# GD32C211 register map
File version: 1.0
GD32C211 ARM 32-bit Cortex-M23 Microcontroller based device
CPU: CM23 r0p0, little endian, MPU, FPU, 4 interrupt priority bits
Registers are 32-bit, read-write, reset 0x0 unless marked. A register's access mark holds for its fields unless they carry their own. Offsets are from the block's base; lines under a group give offsets from that group; [hi:lo] are bit positions; {n}, {i} and the like mark numbered series; 'fields as' and 'values as' point back to an identical list; <NAME> marks a mode.

## Memory map
0x40000400 TIMER2 size 0x400 — General-level0-timers
0x40002000 TIMER13 size 0x400 — General-level0-timers
0x40002800 RTC size 0x400 — Real time clock
0x40002C00 WWDGT size 0x400 — Window watchdog timer
0x40003000 FWDGT size 0x400 — free watchdog timer
0x40003800 SPI1 size 0x400 — Serial peripheral interface
0x40004400 USART1 size 0x400 — Universal synchronous asynchronous receiver transmitter
0x40004800 USART2 size 0x400 — Universal synchronous asynchronous receiver transmitter
0x40005400 I2C0 size 0x400 — Inter integrated circuit
0x40007000 PMU size 0x400 — Power management unit
0x40010000 SYSCFG size 0x400 — System and memory architectur
0x40010400 EXTI size 0x400 — Interrupt / event controller
0x40012400 ADC size 0x400 — Analog-to-digital converter
0x40012C00 TIMER0 size 0x400 — Advanced-timers
0x40013000 SPI0 size 0x400 — Serial Peripheral Interface 0
0x40013800 USART0 size 0x400 — Universal synchronous asynchronous receiver transmitter
0x40014400 TIMER15 size 0x400 — General-level4-timers
0x40014800 TIMER16 size 0x400
0x40015800 DBGMCU size 0x400 — Debug support
0x40020000 DMA size 0x400 — DMA controller
0x40020800 DMAMUX size 0x400 — DMAMUX controller
0x40021000 RCU size 0x400 — Reset and clock unit
0x40022000 FMC size 0x400 — Flash memory controller
0x40023000 CRC size 0x400 — Cyclic redundancy checks management unit
0x48000000 GPIOA size 0x400 — General-purpose I/Os
0x48000400 GPIOB size 0x400 — General-purpose I/Os
0x48000800 GPIOC size 0x400
0x48000C00 GPIOD size 0x400
0x48001400 GPIOF size 0x400
0xE000E100 NVIC size 0xF00 — Nested Vectored Interrupt Controller

## Interrupts
0 WWDGT
2 RTC_GLOBAL (RTC)
3 FMC_GLOBAL (FMC)
5 EXTI0 (EXTI)
6 EXTI01 (EXTI)
7 EXTI2 (EXTI)
8 EXTI3 (EXTI)
9 EXTI4 (EXTI)
10 DMA_Channel0 (DMA)
11 DMA_Channel1 (DMA)
12 DMA_Channel2 (DMA)
13 ADC
14 USART0
15 USART1
16 USART2
17 I2C0_EV (I2C0)
18 I2C0_ER (I2C0)
21 SPI0
22 SPI1
23 RTC_Alarm (RTC)
24 EXTI5_9 (EXTI)
25 TIMER0_TRIG_UP_BREAK (TIMER0)
26 TIMER0_CAP (TIMER0)
27 TIMER2
28 TIMER13
29 TIMER15
30 TIMER16
31 EXTI10_15 (EXTI)
33 DMA_MUX (DMAMUX)
36 I2C0_WAKE (I2C0)
38 USART0_WAKE (USART0)

## CRC — Cyclic redundancy checks management unit
Base 0x40023000
0x00 DATA reset 0xFFFFFFFF
  [31:0] DATA — CRC calculation result bits
0x04 FDATA — Free data register
  [7:0] FDATA — Free data register bits
0x08 CTL — Control register
  [0] RST — Software writes and reads.

## DBGMCU — Debug support
Base 0x40015800
0x00 ID ro — MCU Device ID Code Register
  [31:0] ID_CODE — DBG ID code register
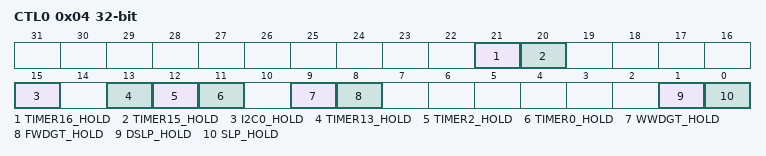
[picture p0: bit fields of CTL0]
0x04 CTL0 — Debug Control Register 0
  [21] TIMER16_HOLD
  [20] TIMER15_HOLD
  [15] I2C0_HOLD
  [13] TIMER13_HOLD
  [12] TIMER2_HOLD
  [11] TIMER0_HOLD — Timer 2 hold register
  [9] WWDGT_HOLD
  [8] FWDGT_HOLD
  [1] DSLP_HOLD — Deep-sleep mode hold bit
  [0] SLP_HOLD — Sleep mode hold register
0x08 CTL1 — Debug Control Register 1
  [10] RTC_HOLD

## DMA — DMA controller
Base 0x40020000
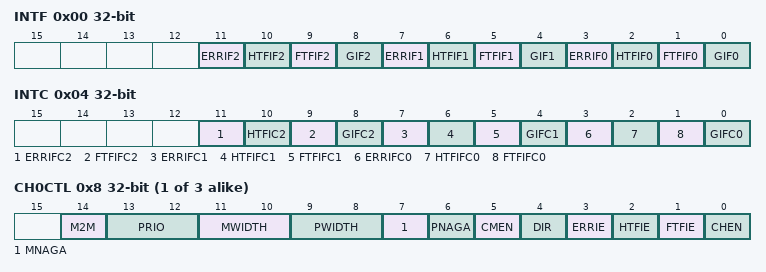
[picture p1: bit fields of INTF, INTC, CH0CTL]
0x00 INTF ro — DMA interrupt flag register (DMA_INTF)
  [11] ERRIF2 — Channel 2 Error flag
  [10] HTFIF2 — Channel 2 Half Transfer Finish flag
  [9] FTFIF2 — Channel 2 Full Transfer Finish flag
  [8] GIF2 — Channel 2 Global interrupt flag
  [7] ERRIF1 — Channel 1 Error flag
  [6] HTFIF1 — Channel 1 Half Transfer Finish flag
  [5] FTFIF1 — Channel 1 Full Transfer Finish flag
  [4] GIF1 — Channel 1 Global interrupt flag
  [3] ERRIF0 — Channel 0 Error flag
  [2] HTFIF0 — Channel 0 Half Transfer Finish flag
  [1] FTFIF0 — Channel 0 Full Transfer Finish flag
  [0] GIF0 — Channel 0 Global interrupt flag
0x04 INTC wo — DMA interrupt flag clear register (DMA_INTC)
  [11] ERRIFC2 — Channel 2 Error clear
  [10] HTFIC2 — Channel 2 Half Transfer clear
  [9] FTFIFC2 — Channel 2 Full Transfer Finish clear
  [8] GIFC2 — Channel 2 Global interrupt flag clear
  [7] ERRIFC1 — Channel 1 Error clear
  [6] HTFIFC1 — Channel 1 Half Transfer clear
  [5] FTFIFC1 — Channel 1 Full Transfer Finish clear
  [4] GIFC1 — Channel 1 Global interrupt flag clear
  [3] ERRIFC0 — Channel 0 Error clear
  [2] HTFIFC0 — Channel 0 Half Transfer clear
  [1] FTFIFC0 — Channel 0 Full Transfer Finish clear
  [0] GIFC0 — Channel 0 Global interrupt flag clear
{0x8+0x14*i} CH{i}CTL (i=0..2) — DMA channel configuration register (DMA_CH{i}CTL)
  [14] M2M — Memory to memory mode
  [13:12] PRIO — Priority Level of this channel
  [11:10] MWIDTH — Transfer data size of memory
  [9:8] PWIDTH — Transfer data size of peripheral
  [7] MNAGA — Next address generation algorithm of memory
  [6] PNAGA — Next address generation algorithm of peripheral
  [5] CMEN — Circular mode enable
  [4] DIR — Transfer direction
  [3] ERRIE — Error interrupt enable
  [2] HTFIE — Half Transfer Finish interrupt enable
  [1] FTFIE — Full Transfer Finish interrupt enable
  [0] CHEN — Channel enable
{0xC+0x14*i} CH{i}CNT (i=0..2) — DMA channel {i} counter register
  [15:0] CNT — Transfer counter
{0x10+0x14*i} CH{i}PADDR (i=0..2) — DMA channel {i} peripheral base address register
  [31:0] PADDR — Peripheral base address
{0x14+0x14*i} CH{i}MADDR (i=0..2) — DMA channel {i} memory base address register
  [31:0] MADDR — Memory address
